# M2354 register map
File version: 1.0
Registers are 32-bit, read-write, reset 0x0 unless marked. A register's access mark holds for its fields unless they carry their own. Offsets are from the block's base; [hi:lo] are bit positions; {n}, {i} and the like mark numbered series.

## GPIOA — GPIO Register Map
Base 0x40004000
Same registers: GPIOA_NS 0x50004000
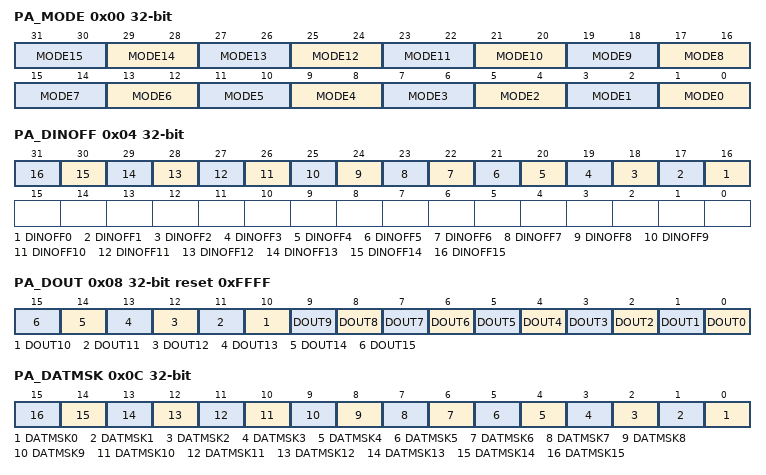
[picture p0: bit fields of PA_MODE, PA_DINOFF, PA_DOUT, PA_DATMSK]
0x00 PA_MODE reset not defined — PA I/O Mode Control
  [all] fields
    0=Px.n is in Input mode (tri-state); 1=Px.n is in Push-pull Output mode; 2=Px.n is in Open-drain Output mode; 3=Px.n is in Quasi-bidirectional mode
  [2n+1:2n] MODE{n} (n=0..15) — Port A-H I/O Pin[n] Mode Control. Determine each I/O mode of Px.n pins. Note 1: The initial value of this field is defined by CIOINI (CONFIG0 [10]).If CIOINI is set to 0, the default value is 0xFFFF_FFFF and all pins will be quasi-bidirectional mode after chip powered on.If CIOINI is set to 1, the default value is 0x0000_0000 and all pins will be input mode after chip powered on. Note 2: The PC.14/PC.15/ PD.13/ PD.15/ PF.12~15/ PG.0/ PG.1/ PG.5~8/ PH.0~3/ PH.12~15 pin is ignored. Note 3: If MFOS is enabled then GPIO mode setting is ignored.
0x04 PA_DINOFF — PA Digital Input Path Disable Control
  [all] fields
    0=Px.n digital input path Enabled; 1=Px.n digital input path Disabled (digital input tied to low)
  [n+16] DINOFF{n} (n=0..15) — Port A-H Pin[n] Digital Input Path Disable Bit. Each of these bits is used to control if the digital input path of corresponding Px.n pin is disabled. If input is analog signal, users can disable Px.n digital input path to avoid input current leakage. Note: The PC.14/PC.15/ PD.13/ PD.15/ PF.12~15/ PG.0/ PG.1/ PG.5~8/ PH.0~3/ PH.12~15 pin is ignored.
0x08 PA_DOUT reset 0xFFFF — PA Data Output Value
  [all] fields
    0=Px.n will drive Low if the Px.n pin is configured as Push-pull output, Open-drain output or Quasi-bidirectional mode; 1=Px.n will drive High if the Px.n pin is configured as Push-pull output or Quasi-bidirectional mode
  [n] DOUT{n} (n=0..15) — Port A-H Pin[n] Output Value. Each of these bits controls the status of a Px.n pin when the Px.n is configured as Push-pull output, Open-drain output or Quasi-bidirectional mode. Note: The PC.14/PC.15/ PD.13/ PD.15/ PF.12~15/ PG.0/ PG.1/ PG.5~8/ PH.0~3/ PH.12~15 pin is ignored.
0x0C PA_DATMSK — PA Data Output Write Mask
  [all] fields
    0=Corresponding DOUT (Px_DOUT[n]) bit can be updated; 1=Corresponding DOUT (Px_DOUT[n]) bit protected
  [n] DATMSK{n} (n=0..15) — Port A-H Pin[n] Data Output Write Mask. These bits are used to protect the corresponding DOUT (Px_DOUT[n]) bit. When the DATMSK (Px_DATMSK[n]) bit is set to 1, the corresponding DOUT (Px_DOUT[n]) bit is protected. If the write signal is masked, writing data to the protect bit is ineffective. Note 1: This function only protects the corresponding DOUT (Px_DOUT[n]) bit, and will not protect the corresponding PDIO (Pxn_PDIO[0]) bit. Note 2: The PC.14/PC.15/ PD.13/ PD.15/ PF.12~15/ PG.0/ PG.1/ PG.5~8/ PH.0~3/ PH.12~15 pin is ignored.
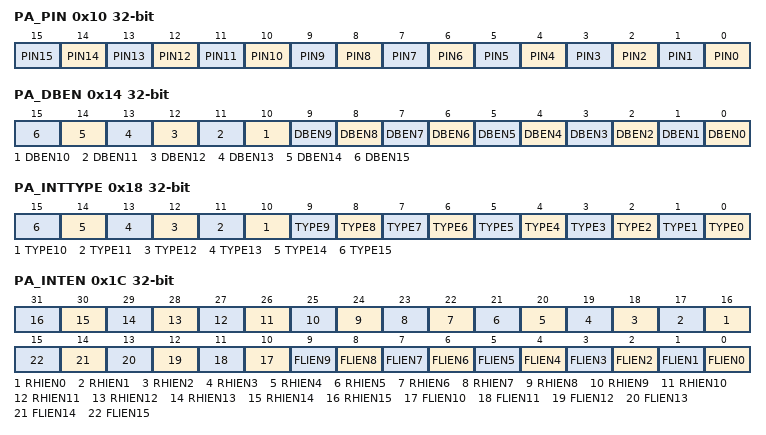
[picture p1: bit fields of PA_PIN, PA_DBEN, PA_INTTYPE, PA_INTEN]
0x10 PA_PIN ro (reset mask 0xFFFF0000) — PA Pin Value
  [all] fields
    0=The corresponding pin status is low; 1=The corresponding pin status is high
  [n] PIN{n} (n=0..15) — Port A-H Pin[n] Pin Value. Each bit of the register reflects the actual status of the respective Px.n pin. Note: The PC.14/PC.15/ PD.13/ PD.15/ PF.12~15/ PG.0/ PG.1/ PG.5~8/ PH.0~3/ PH.12~15 pin is ignored.
0x14 PA_DBEN — PA De-bounce Enable Control Register
  [all] fields
    0=Px.n de-bounce function Disabled; 1=Px.n de-bounce function Enabled
  [n] DBEN{n} (n=0..15) — Port A-H Pin[n] Input Signal De-bounce Enable Bit. The DBEN[n] bit is used to enable the de-bounce function for each corresponding bit. If the input signal pulse width cannot be sampled by continuous two de-bounce sample cycle, the input signal transition is seen as the signal bounce and will not trigger the interrupt. The de-bounce clock source is controlled by DBCLKSRC (Px_DBCTL [4]), one de-bounce sample cycle period is controlled by DBCLKSEL (Px_DBCTL [3:0]). The de-bounce function is valid only for edge triggered interrupt. If the interrupt mode is level triggered, the de-bounce enable bit is ineffective. Note: The PC.14/PC.15/ PD.13/ PD.15/ PF.12~15/ PG.0/ PG.1/ PG.5~8/ PH.0~3/ PH.12~15 pin is ignored.
0x18 PA_INTTYPE — PA Interrupt Trigger Type Control
  [all] fields
    0=Edge trigger interrupt; 1=Level trigger interrupt
  [n] TYPE{n} (n=0..15) — Port A-H Pin[n] Edge or Level Detection Interrupt Trigger Type Control. TYPE (Px_INTTYPE[n]) bit is used to control the triggered interrupt is by level trigger or by edge trigger. If the interrupt is by edge trigger, the trigger source can be controlled by de-bounce. If the interrupt is by level trigger, the input source is sampled by one HCLK clock and generates the interrupt. If the pin is set as the level trigger interrupt, only one level can be set on the registers RHIEN (Px_INTEN[n+16])/FLIEN (Px_INTEN[n]). If both levels to trigger interrupt are set, the setting has no effect and no interrupt will occur. The de-bounce function is valid only for edge triggered interrupt. If the interrupt mode is level triggered, the de-bounce enable bit is ineffective. Note: The PC.14/PC.15/ PD.13/ PD.15/ PF.12~15/ PG.0/ PG.1/ PG.5~8/ PH.0~3/ PH.12~15 pin is ignored.
0x1C PA_INTEN — PA Interrupt Enable Control Register
  [n+16] RHIEN{n} (n=0..15) — Port A-H Pin[n] Rising Edge or High Level Interrupt Trigger Type Enable Bit. The RHIEN (Px_INTEN[n+16]) bit is used to enable the interrupt for each of the corresponding input Px.n pin. Set bit to 1 also enable the pin wake-up function. When setting the RHIEN (Px_INTEN[n+16]) bit to 1 : If the interrupt is level trigger (TYPE (Px_INTTYPE[n]) bit is set to 1), the input Px.n pin will generate the interrupt while this pin state is at high level. If the interrupt is edge trigger (TYPE (Px_INTTYPE[n]) bit is set to 0), the input Px.n pin will generate the interrupt while this pin state changed from low to high. Note: The PC.14/PC.15/ PD.13/ PD.15/ PF.12~15/ PG.0/ PG.1/ PG.5~8/ PH.0~3/ PH.12~15 pin is ignored.
    0=Px.n level high or low to high interrupt Disabled; 1=Px.n level high or low to high interrupt Enabled
  [n] FLIEN{n} (n=0..15) — Port A-H Pin[n] Falling Edge or Low Level Interrupt Trigger Type Enable Bit. The FLIEN (Px_INTEN[n]) bit is used to enable the interrupt for each of the corresponding input Px.n pin. Set bit to 1 also enable the pin wake-up function. When setting the FLIEN (Px_INTEN[n]) bit to 1 : If the interrupt is level trigger (TYPE (Px_INTTYPE[n]) bit is set to 1), the input Px.n pin will generate the interrupt while this pin state is at low level. If the interrupt is edge trigger(TYPE (Px_INTTYPE[n]) bit is set to 0), the input Px.n pin will generate the interrupt while this pin state changed from high to low. Note: The PC.14/PC.15/ PD.13/ PD.15/ PF.12~15/ PG.0/ PG.1/ PG.5~8/ PH.0~3/ PH.12~15 pin is ignored.
    0=Px.n level low or high to low interrupt Disabled; 1=Px.n level low or high to low interrupt Enabled
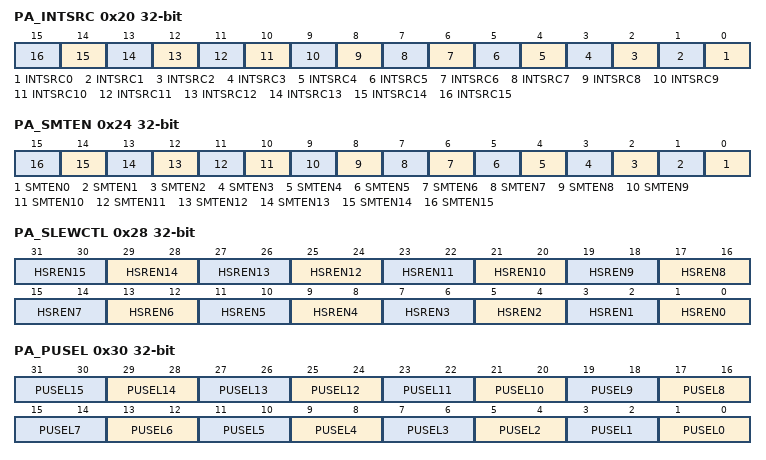
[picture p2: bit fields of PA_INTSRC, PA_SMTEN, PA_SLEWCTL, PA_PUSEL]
0x20 PA_INTSRC (reset mask 0xFFFF0000) — PA Interrupt Source Flag
  [all] fields
    0=No action. No interrupt at Px.n; 1=Clear the corresponding pending interrupt. Px.n generates an interrupt
  [n] INTSRC{n} (n=0..15) — Port A-H Pin[n] Interrupt Source Flag. Write Operation: Note: The PC.14/PC.15/ PD.13/ PD.15/ PF.12~15/ PG.0/ PG.1/ PG.5~8/ PH.0~3/ PH.12~15 pin is ignored.
0x24 PA_SMTEN — PA Input Schmitt Trigger Enable Register
  [all] fields
    0=Px.n input schmitt trigger function Disabled; 1=Px.n input schmitt trigger function Enabled
  [n] SMTEN{n} (n=0..15) — Port A-H Pin[n] Input Schmitt Trigger Enable Bit. Note: The PC.14/PC.15/ PD.13/ PD.15/ PF.12~15/ PG.0/ PG.1/ PG.5~8/ PH.0~3/ PH.12~15 pin is ignored.
0x28 PA_SLEWCTL — PA High Slew Rate Control Register
  [all] fields
    0=Px.n output with normal slew rate mode; 1=Px.n output with high slew rate mode; 2=Px.n output with fast slew rate mode
  [2n+1:2n] HSREN{n} (n=0..15) — Port A-H Pin[n] High Slew Rate Control. Note 1: The PC.14/PC.15/ PD.13/ PD.15/ PF.12~15/ PG.0/ PG.1/ PG.5~8/ PH.0~3/ PH.12~15 pin is ignored. Note 2: Please refer to the M2354 Datasheet for detailed pin operation voltage information about VDD, VDDIO and VBAT electrical characteristics.
0x30 PA_PUSEL — PA Pull-up and Pull-down Selection Register
  [all] fields
    0=Px.n pull-up and pull-down disabled; 1=Px.n pull-up enabled; 2=Px.n pull-down enabled; 3=Px.n pull-up and pull- down disabled
  [2n+1:2n] PUSEL{n} (n=0..15) — Port A-H Pin[n] Pull-up and Pull-down Enable Register. Determine each I/O Pull-up/pull-down of Px.n pins. Note 1: Basically, the pull-up control and pull-down control has following behavior limitation. The independent pull-up control register only valid when MODEn set as input and open-drain mode even if I/O function is switched to multi-function pin. Ex: UARTx_RXD. The independent pull-down control register only valid when MODEn set as tri-state mode. When both pull-uppull-down is set as 1 at 'tri-state' mode, keep I/O in tri-state mode. Note 2: The PC.14/PC.15/ PD.13/ PD.15/ PF.12~15/ PG.0/ PG.1/ PG.5~8/ PH.0~3/ PH.12~15 pin is ignored.
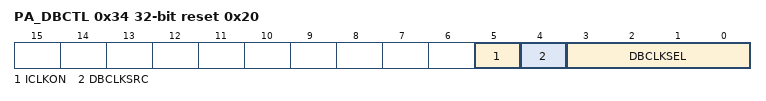
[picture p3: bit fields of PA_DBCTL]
0x34 PA_DBCTL reset 0x20 — PA Interrupt De-bounce Control Register
  [5] ICLKON — Interrupt Clock on Mode (Secure Only). Note 3: This bit is only accessible from the Secure state.
    0=Edge detection circuit is active only if I/O pin corresponding RHIEN (Px_INTEN[n+16])/FLIEN (Px_INTEN[n]) bit is set to 1; 1=All I/O pins edge detection circuit is always active after reset
  [4] DBCLKSRC — De-bounce Counter Clock Source Selection (Secure only). Note: This bit is only accessible from the Secure state.
    0=De-bounce counter clock source is the HCLK; 1=De-bounce counter clock source is the 32 kHz internal low speed RC oscillator (LIRC)
  [3:0] DBCLKSEL — De-bounce Sampling Cycle Selection (Secure only). Note: These bits are only accessible from the Secure state.
    0=Sample interrupt input once per 1 clocks; 1=Sample interrupt input once per 2 clocks; 2=Sample interrupt input once per 4 clocks; 3=Sample interrupt input once per 8 clocks; 4=Sample interrupt input once per 16 clocks; 5=Sample interrupt input once per 32 clocks; 6=Sample interrupt input once per 64 clocks; 7=Sample interrupt input once per 128 clocks; 8=Sample interrupt input once per 256 clocks; 9=Sample interrupt input once per 2*256 clocks; 10=Sample interrupt input once per 4*256 clocks; 11=Sample interrupt input once per 8*256 clocks; 12=Sample interrupt input once per 16*256 clocks; 13=Sample interrupt input once per 32*256 clocks; 14=Sample interrupt input once per 64*256 clocks; 15=Sample interrupt input once per 128*256 clocks
